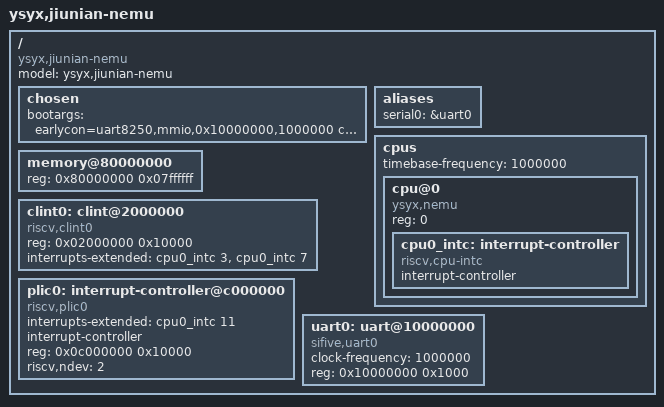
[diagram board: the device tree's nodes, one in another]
/dts-v1/;


/ {
	compatible = "ysyx,jiunian-nemu";
	model = "ysyx,jiunian-nemu";
	#address-cells = <1>;
	#size-cells = <1>;
	chosen {
		bootargs = "earlycon=uart8250,mmio,0x10000000,1000000 console=ttyS0,1000000n8";
	};

	aliases {
		serial0 = &uart0;
	};

	cpus {
		#address-cells = <1>;
		#size-cells = <0>;
		timebase-frequency = <1000000>;
		cpu@0 {
			phandle = <1>;
			device_type = "cpu";
			compatible = "ysyx,nemu", "riscv";
			reg = <0>;
			status = "okay";

			cpu0_intc: interrupt-controller {
				phandle = <2>;
				#interrupt-cells = <1>;
        #address-cells = <0>;
				compatible = "riscv,cpu-intc";
				interrupt-controller;
			};
		};
	};

	memory@80000000 {
		device_type = "memory";
		reg = <0x80000000 0x07ffffff>;
	};

	clint0: clint@2000000 {
		compatible = "riscv,clint0";
		reg = <0x02000000 0x10000>;
		interrupts-extended = <&cpu0_intc 3 &cpu0_intc 7>;
	};

	plic0: interrupt-controller@c000000{
		phandle = <3>;
		compatible = "riscv,plic0";
		interrupts-extended = <&cpu0_intc 11>;
    interrupt-controller;
    #interrupt-cells = <1>;
    #address-cells = <0>;
		reg = <0x0c000000 0x10000>;
    riscv,ndev = <2>;
	};

	uart0: uart@10000000{
		compatible = "sifive,uart0", "ysyx,nemu-uart", "ns16550";
		clock-frequency = <1000000>;
		reg = <0x10000000 0x1000>;
    // interrupt-parent = <&plic0>;
    // interrupts = <10>;
	};

};
